# CY8C5868AXI_LP035 register map
File version: 0.1
Registers are 8-bit, read-write, no defined reset value unless marked. A register's access mark holds for its fields unless they carry their own. Offsets are from the block's base; [hi:lo] are bit positions; {n}, {i} and the like mark numbered series; 'fields as' and 'values as' point back to an identical list.

## C12880_TRG
Base 0x00000000
0x40006526 C12880_TRG_COMPARE_Reg 16-bit — UDB.D0 - Assigned Compare Value
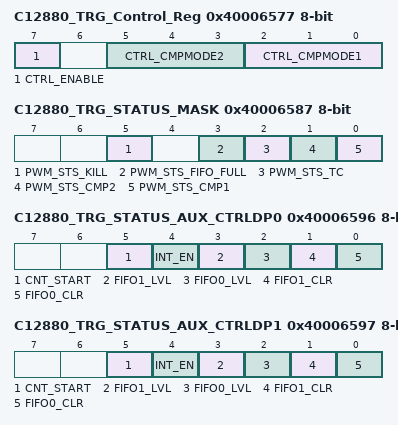
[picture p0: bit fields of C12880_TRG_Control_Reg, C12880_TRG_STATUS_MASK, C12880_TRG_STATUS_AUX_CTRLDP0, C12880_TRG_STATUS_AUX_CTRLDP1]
0x40006577 C12880_TRG_Control_Reg — UDB Control Register - Assigned Control Register Value
  [7] CTRL_ENABLE — Enable the PWM
  [5:3] CTRL_CMPMODE2 — Compare mode 2
  [2:0] CTRL_CMPMODE1 — Compare mode 1
0x40006587 C12880_TRG_STATUS_MASK — UDB Status bits Interrupt Mask Enable Register
  [5] PWM_STS_KILL ro — Enables the Interrupt on Kill
  [3] PWM_STS_FIFO_FULL ro — FIFO Full Status Mask
  [2] PWM_STS_TC ro — Enables the Interrupt on Terminal Count
  [1] PWM_STS_CMP2 ro — Enables the Interrupt on Compare 2
  [0] PWM_STS_CMP1 ro — Enables the Interrupt on Compare 1
0x40006596 C12880_TRG_STATUS_AUX_CTRLDP0 — UDB Auxilliary Control Register
  [5] CNT_START — FIFO0 clear
    0=E_CNT_START0 (Disable counter); 1=E_CNT_START1 (Enable counter)
  [4] INT_EN
    0=E_INT_EN0 (Interrupt disabled); 1=E_INT_EN1 (Interrupt enabled)
  [3] FIFO1_LVL — FIFO level
    0=E_FIFO_LVL_0 (FIFO LVL: input mode: FIFO not full; output mode: FIFO not empty); 1=E_FIFO_LVL_1 (FIFO LVL: input mode: FIFO at least 1/2 empty; output mode: FIFO at least 1/2 full)
  [2] FIFO0_LVL — FIFO level
    values as FIFO1_LVL
  [1] FIFO1_CLR — FIFO1 clear
    0=E_FIFO_CLR_0 (Normal FIFO operation); 1=E_FIFO_CLR_1 (Clear FIFO state)
  [0] FIFO0_CLR — FIFO0 clear
    values as FIFO1_CLR
0x40006597 C12880_TRG_STATUS_AUX_CTRLDP1 — UDB Auxilliary Control Register
  fields as C12880_TRG_STATUS_AUX_CTRLDP0

## C12880_CLK
Base 0x00000000
0x40006424 C12880_CLK_COMPARE_Reg 16-bit — UDB.D0 - Assigned Compare Value
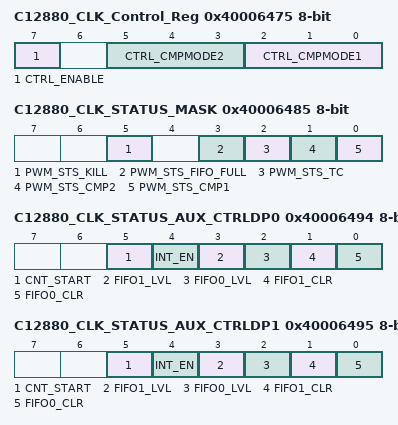
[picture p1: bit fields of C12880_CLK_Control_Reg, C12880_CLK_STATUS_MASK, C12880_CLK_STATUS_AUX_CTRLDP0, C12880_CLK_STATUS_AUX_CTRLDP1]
0x40006475 C12880_CLK_Control_Reg — UDB Control Register - Assigned Control Register Value
  [7] CTRL_ENABLE — Enable the PWM
  [5:3] CTRL_CMPMODE2 — Compare mode 2
  [2:0] CTRL_CMPMODE1 — Compare mode 1
0x40006485 C12880_CLK_STATUS_MASK — UDB Status bits Interrupt Mask Enable Register
  [5] PWM_STS_KILL ro — Enables the Interrupt on Kill
  [3] PWM_STS_FIFO_FULL ro — FIFO Full Status Mask
  [2] PWM_STS_TC ro — Enables the Interrupt on Terminal Count
  [1] PWM_STS_CMP2 ro — Enables the Interrupt on Compare 2
  [0] PWM_STS_CMP1 ro — Enables the Interrupt on Compare 1
0x40006494 C12880_CLK_STATUS_AUX_CTRLDP0 — UDB Auxilliary Control Register
  [5] CNT_START — FIFO0 clear
    0=E_CNT_START0 (Disable counter); 1=E_CNT_START1 (Enable counter)
  [4] INT_EN
    0=E_INT_EN0 (Interrupt disabled); 1=E_INT_EN1 (Interrupt enabled)
  [3] FIFO1_LVL — FIFO level
    0=E_FIFO_LVL_0 (FIFO LVL: input mode: FIFO not full; output mode: FIFO not empty); 1=E_FIFO_LVL_1 (FIFO LVL: input mode: FIFO at least 1/2 empty; output mode: FIFO at least 1/2 full)
  [2] FIFO0_LVL — FIFO level
    values as FIFO1_LVL
  [1] FIFO1_CLR — FIFO1 clear
    0=E_FIFO_CLR_0 (Normal FIFO operation); 1=E_FIFO_CLR_1 (Clear FIFO state)
  [0] FIFO0_CLR — FIFO0 clear
    values as FIFO1_CLR
0x40006495 C12880_CLK_STATUS_AUX_CTRLDP1 — UDB Auxilliary Control Register
  fields as C12880_CLK_STATUS_AUX_CTRLDP0

## ADC — SAR ADC
Base 0x00000000
0x40004616 SAR_TR0 — SAR trim register
{0x40005908+i} SAR_CSR{i} (i=0..6) — SAR status and control register {i}
0x40005B28 SAR_SW0 — SAR Analog Routing Register 0
{0x40005B28+i} SAR_SW{i} (i=2..4) — SAR Analog Routing Register {i}
0x40005B2E SAR_SW6 — SAR Analog Routing Register 6
0x40005B2F SAR_CLK — SAR Clock Selection Register
0x40005BA2 SAR_WRK 16-bit — SAR working register

## C12880_ST
Base 0x00000000
0x40006426 C12880_ST_COMPARE_Reg 16-bit — UDB.D0 - Assigned Compare Value
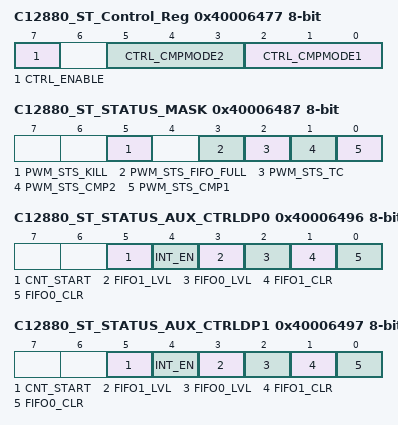
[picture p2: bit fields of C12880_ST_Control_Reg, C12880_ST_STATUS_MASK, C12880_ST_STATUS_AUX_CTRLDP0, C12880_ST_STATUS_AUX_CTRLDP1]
0x40006477 C12880_ST_Control_Reg — UDB Control Register - Assigned Control Register Value
  [7] CTRL_ENABLE — Enable the PWM
  [5:3] CTRL_CMPMODE2 — Compare mode 2
  [2:0] CTRL_CMPMODE1 — Compare mode 1
0x40006487 C12880_ST_STATUS_MASK — UDB Status bits Interrupt Mask Enable Register
  [5] PWM_STS_KILL ro — Enables the Interrupt on Kill
  [3] PWM_STS_FIFO_FULL ro — FIFO Full Status Mask
  [2] PWM_STS_TC ro — Enables the Interrupt on Terminal Count
  [1] PWM_STS_CMP2 ro — Enables the Interrupt on Compare 2
  [0] PWM_STS_CMP1 ro — Enables the Interrupt on Compare 1
0x40006496 C12880_ST_STATUS_AUX_CTRLDP0 — UDB Auxilliary Control Register
  [5] CNT_START — FIFO0 clear
    0=E_CNT_START0 (Disable counter); 1=E_CNT_START1 (Enable counter)
  [4] INT_EN
    0=E_INT_EN0 (Interrupt disabled); 1=E_INT_EN1 (Interrupt enabled)
  [3] FIFO1_LVL — FIFO level
    0=E_FIFO_LVL_0 (FIFO LVL: input mode: FIFO not full; output mode: FIFO not empty); 1=E_FIFO_LVL_1 (FIFO LVL: input mode: FIFO at least 1/2 empty; output mode: FIFO at least 1/2 full)
  [2] FIFO0_LVL — FIFO level
    values as FIFO1_LVL
  [1] FIFO1_CLR — FIFO1 clear
    0=E_FIFO_CLR_0 (Normal FIFO operation); 1=E_FIFO_CLR_1 (Clear FIFO state)
  [0] FIFO0_CLR — FIFO0 clear
    values as FIFO1_CLR
0x40006497 C12880_ST_STATUS_AUX_CTRLDP1 — UDB Auxilliary Control Register
  fields as C12880_ST_STATUS_AUX_CTRLDP0

## C12880_ctrl_reg
Base 0x00000000
0x40006474 C12880_ctrl_reg_CONTROL_REG
